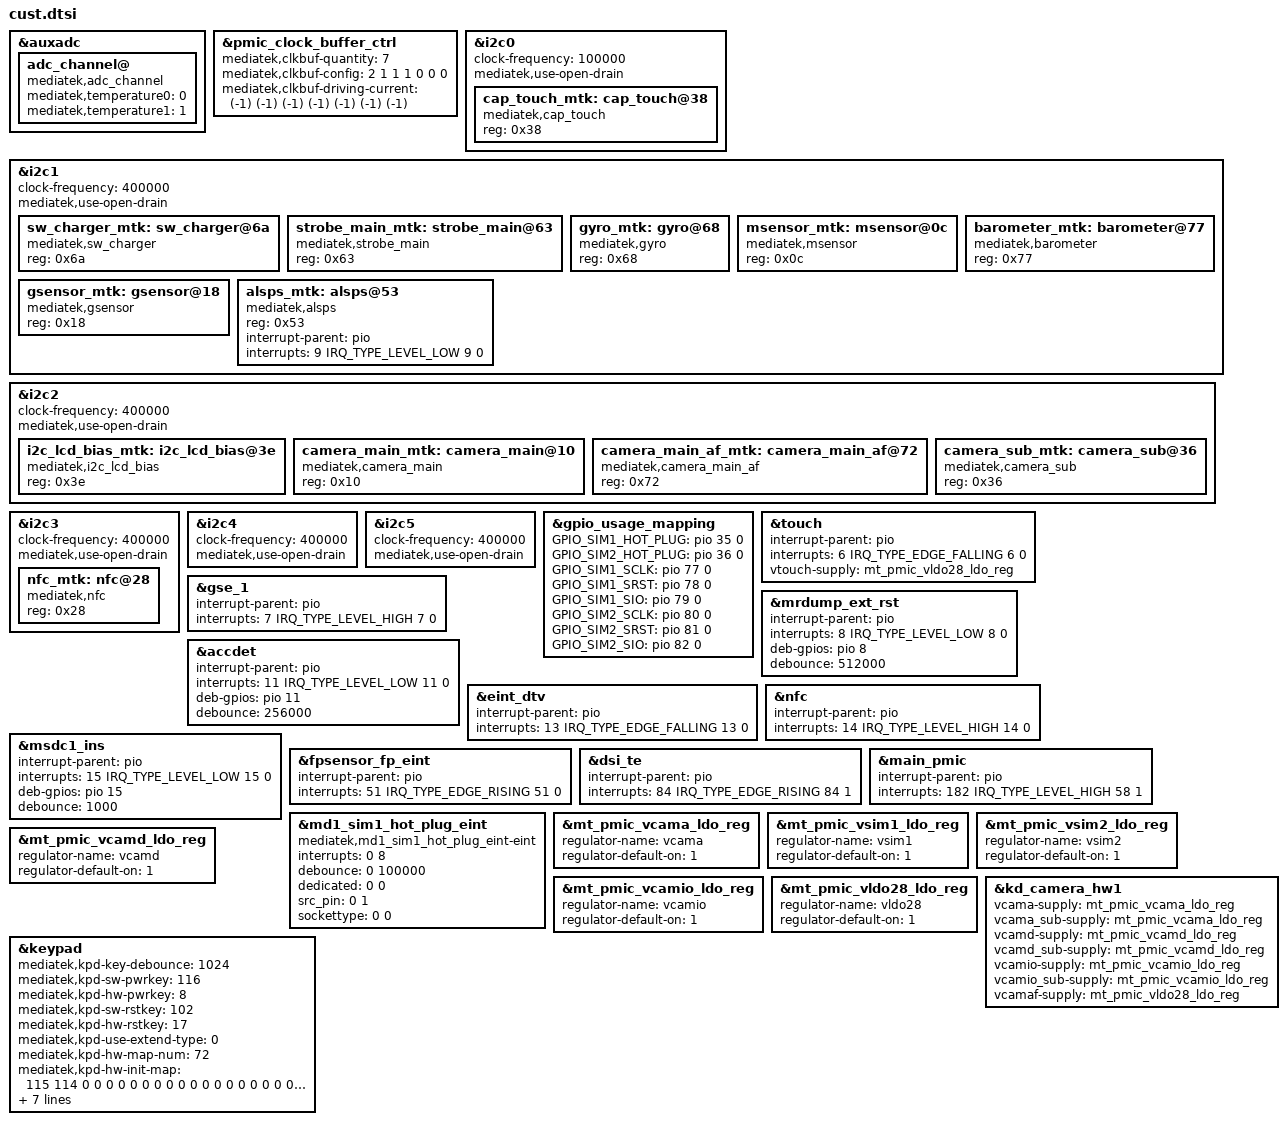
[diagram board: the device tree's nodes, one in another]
/*
 * Generated by MTK SP DrvGen Version: 3.5.160809 for MT6739.
 * 2019-04-21 21:38:27
 * Do Not Modify The File.
 * Copyright Mediatek Inc. (c) 2016.
*/

/*************************
 * ADC DTSI File
*************************/

&auxadc {
	adc_channel@ {
		compatible = "mediatek,adc_channel";
		mediatek,temperature0 = <0>;
		mediatek,temperature1 = <1>;
		status = "okay";
	};
};


/*************************
 * CLK_BUF DTSI File
*************************/

&pmic_clock_buffer_ctrl {
	mediatek,clkbuf-quantity = <7>;
	mediatek,clkbuf-config = <2 1 1 1 0 0 0>;
	mediatek,clkbuf-driving-current = <(-1) (-1) (-1) (-1) (-1) (-1) (-1)>;
	status = "okay";
};


/*************************
 * I2C DTSI File
*************************/

&i2c0 {
	#address-cells = <1>;
	#size-cells = <0>;
	clock-frequency = <100000>;
	mediatek,use-open-drain;
	cap_touch_mtk:cap_touch@38 {
		compatible = "mediatek,cap_touch";
		reg = <0x38>;
		status = "okay";
	};

};

&i2c1 {
	#address-cells = <1>;
	#size-cells = <0>;
	clock-frequency = <400000>;
	mediatek,use-open-drain;
	sw_charger_mtk:sw_charger@6a {
		compatible = "mediatek,sw_charger";
		reg = <0x6a>;
		status = "okay";
	};

	strobe_main_mtk:strobe_main@63 {
		compatible = "mediatek,strobe_main";
		reg = <0x63>;
		status = "okay";
	};

	gyro_mtk:gyro@68 {
		compatible = "mediatek,gyro";
		reg = <0x68>;
		status = "okay";
	};

	msensor_mtk:msensor@0c {
		compatible = "mediatek,msensor";
		reg = <0x0c>;
		status = "okay";
	};

	barometer_mtk:barometer@77 {
		compatible = "mediatek,barometer";
		reg = <0x77>;
		status = "okay";
	};

	gsensor_mtk:gsensor@18 {
		compatible = "mediatek,gsensor";
		reg = <0x18>;
		status = "okay";
	};

	alsps_mtk:alsps@53 {
		compatible = "mediatek,alsps";
		reg = <0x53>;
		status = "okay";
	};

};

&i2c2 {
	#address-cells = <1>;
	#size-cells = <0>;
	clock-frequency = <400000>;
	mediatek,use-open-drain;
	i2c_lcd_bias_mtk:i2c_lcd_bias@3e {
		compatible = "mediatek,i2c_lcd_bias";
		reg = <0x3e>;
		status = "okay";
	};

	camera_main_mtk:camera_main@10 {
		compatible = "mediatek,camera_main";
		reg = <0x10>;
		status = "okay";
	};

	camera_main_af_mtk:camera_main_af@72 {
		compatible = "mediatek,camera_main_af";
		reg = <0x72>;
		status = "okay";
	};

	camera_sub_mtk:camera_sub@36 {
		compatible = "mediatek,camera_sub";
		reg = <0x36>;
		status = "okay";
	};

};

&i2c3 {
	#address-cells = <1>;
	#size-cells = <0>;
	clock-frequency = <400000>;
	mediatek,use-open-drain;
	nfc_mtk:nfc@28 {
		compatible = "mediatek,nfc";
		reg = <0x28>;
		status = "okay";
	};

};

&i2c4 {
	#address-cells = <1>;
	#size-cells = <0>;
	clock-frequency = <400000>;
	mediatek,use-open-drain;
};

&i2c5 {
	#address-cells = <1>;
	#size-cells = <0>;
	clock-frequency = <400000>;
	mediatek,use-open-drain;
};



/*************************
 * GPIO DTSI File
*************************/

&gpio_usage_mapping {
	GPIO_SIM1_HOT_PLUG = <&pio 35 0>;
	GPIO_SIM2_HOT_PLUG = <&pio 36 0>;
	GPIO_SIM1_SCLK = <&pio 77 0>;
	GPIO_SIM1_SRST = <&pio 78 0>;
	GPIO_SIM1_SIO = <&pio 79 0>;
	GPIO_SIM2_SCLK = <&pio 80 0>;
	GPIO_SIM2_SRST = <&pio 81 0>;
	GPIO_SIM2_SIO = <&pio 82 0>;
};


/*************************
 * EINT DTSI File
*************************/

#include <dt-bindings/interrupt-controller/irq.h>
#include <dt-bindings/interrupt-controller/arm-gic.h>

&touch {
	interrupt-parent = <&pio>;
	interrupts = <6 IRQ_TYPE_EDGE_FALLING 6 0>;
	status = "okay";
};

&gse_1 {
	interrupt-parent = <&pio>;
	interrupts = <7 IRQ_TYPE_LEVEL_HIGH 7 0>;
	status = "okay";
};

&mrdump_ext_rst {
	interrupt-parent = <&pio>;
	interrupts = <8 IRQ_TYPE_LEVEL_LOW 8 0>;
	deb-gpios = <&pio 8 0>;
	debounce = <512000>;
	status = "okay";
};

&alsps_mtk {
	interrupt-parent = <&pio>;
	interrupts = <9 IRQ_TYPE_LEVEL_LOW 9 0>;
	status = "okay";
};

&accdet {
	interrupt-parent = <&pio>;
	interrupts = <11 IRQ_TYPE_LEVEL_LOW 11 0>;
	deb-gpios = <&pio 11 0>;
	debounce = <256000>;
	status = "okay";
};

&eint_dtv {
	interrupt-parent = <&pio>;
	interrupts = <13 IRQ_TYPE_EDGE_FALLING 13 0>;
	status = "okay";
};

&nfc {
	interrupt-parent = <&pio>;
	interrupts = <14 IRQ_TYPE_LEVEL_HIGH 14 0>;
	status = "okay";
};

&msdc1_ins {
	interrupt-parent = <&pio>;
	interrupts = <15 IRQ_TYPE_LEVEL_LOW 15 0>;
	deb-gpios = <&pio 15 0>;
	debounce = <1000>;
	status = "okay";
};

&fpsensor_fp_eint {
	interrupt-parent = <&pio>;
	interrupts = <51 IRQ_TYPE_EDGE_RISING 51 0>;
	status = "okay";
};

&dsi_te {
	interrupt-parent = <&pio>;
	interrupts = <84 IRQ_TYPE_EDGE_RISING 84 1>;
	status = "okay";
};

&main_pmic {
	interrupt-parent = <&pio>;
	interrupts = <182 IRQ_TYPE_LEVEL_HIGH 58 1>;
	status = "okay";
};



/*************************
 * MD1_EINT DTSI File
*************************/

&md1_sim1_hot_plug_eint {
	compatible = "mediatek,md1_sim1_hot_plug_eint-eint";
	interrupts = <0 8>;
	debounce = <0 100000>;
	dedicated = <0 0>;
	src_pin = <0 1>;
	sockettype = <0 0>;
	status = "okay";
};



/*************************
 * PMIC DTSI File
*************************/

&mt_pmic_vcama_ldo_reg {
	regulator-name = "vcama";
	regulator-default-on = <1>; /* 0:skip, 1: off, 2:on */
	status = "okay";
};
&mt_pmic_vsim1_ldo_reg {
	regulator-name = "vsim1";
	regulator-default-on = <1>; /* 0:skip, 1: off, 2:on */
	status = "okay";
};
&mt_pmic_vsim2_ldo_reg {
	regulator-name = "vsim2";
	regulator-default-on = <1>; /* 0:skip, 1: off, 2:on */
	status = "okay";
};
&mt_pmic_vcamd_ldo_reg {
	regulator-name = "vcamd";
	regulator-default-on = <1>; /* 0:skip, 1: off, 2:on */
	status = "okay";
};
&mt_pmic_vcamio_ldo_reg {
	regulator-name = "vcamio";
	regulator-default-on = <1>; /* 0:skip, 1: off, 2:on */
	status = "okay";
};
&mt_pmic_vldo28_ldo_reg {
	regulator-name = "vldo28";
	regulator-default-on = <1>; /* 0:skip, 1: off, 2:on */
	status = "okay";
};

&kd_camera_hw1 {
	vcama-supply = <&mt_pmic_vcama_ldo_reg>;
	vcama_sub-supply = <&mt_pmic_vcama_ldo_reg>;
	vcamd-supply = <&mt_pmic_vcamd_ldo_reg>;
	vcamd_sub-supply = <&mt_pmic_vcamd_ldo_reg>;
	vcamio-supply = <&mt_pmic_vcamio_ldo_reg>;
	vcamio_sub-supply = <&mt_pmic_vcamio_ldo_reg>;
	vcamaf-supply = <&mt_pmic_vldo28_ldo_reg>;
	status = "okay";
};

&touch {
	vtouch-supply = <&mt_pmic_vldo28_ldo_reg>;
	status = "okay";
};


/*************************
 * POWER DTSI File
*************************/



/*************************
 * KPD DTSI File
*************************/

&keypad {
	mediatek,kpd-key-debounce = <1024>;
	mediatek,kpd-sw-pwrkey = <116>;
	mediatek,kpd-hw-pwrkey = <8>;
	mediatek,kpd-sw-rstkey  = <102>;
	mediatek,kpd-hw-rstkey = <17>;
	mediatek,kpd-use-extend-type = <0>;
	/*HW Keycode [0~71] -> Linux Keycode*/
	mediatek,kpd-hw-map-num = <72>;
	mediatek,kpd-hw-init-map = <115 114 0 0 0 0 0 0 0 0 0 0 0 0 0 0 0 0 0 0 0 0 0 0 0 0 0 0 0 0 0 0 0 0 0 0 0 0 0 0 0 0 0 0 0 0 0 0 0 0 0 0 0 0 0 0 0 0 0 0 0 0 0 0 0 0 0 0 0 0 0 0 >;
	mediatek,kpd-pwrkey-eint-gpio = <0>;
	mediatek,kpd-pwkey-gpio-din  = <0>;
	mediatek,kpd-hw-dl-key0 = <0>;
	mediatek,kpd-hw-dl-key1 = <1>;
	mediatek,kpd-hw-dl-key2 = <8>;
	mediatek,kpd-hw-recovery-key = <0>;
	mediatek,kpd-hw-factory-key = <1>;
	status = "okay";
};


